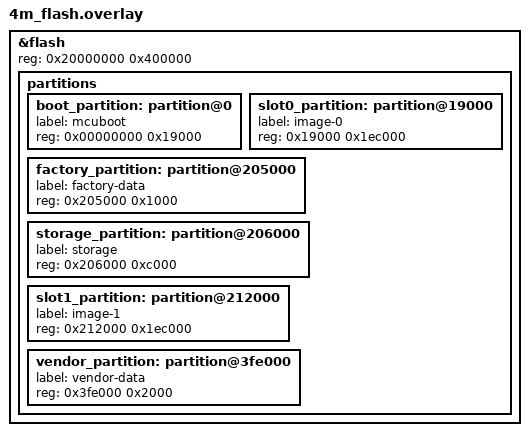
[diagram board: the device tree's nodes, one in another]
/*
 * In case of change partitions size - check if factory data size is correct
 * in matter/connectedhomeip/config/telink/chip-module/CMakeLists.txt, variable "FD_SEEK"
 * Also check matter/connectedhomeip/config/telink/chip-module/generate_factory_data.cmake,
 * variable "FD_OFFSET" and argument "size"
 */

&flash {
	reg = <0x20000000 0x400000>;

	partitions {
		/delete-node/ partition@0;
		/delete-node/ partition@20000;
		/delete-node/ partition@88000;
		/delete-node/ partition@f0000;
		/delete-node/ partition@f4000;
		/delete-node/ partition@fe000;
		boot_partition: partition@0 {
			label = "mcuboot";
			reg = <0x00000000 0x19000>;
		};
		slot0_partition: partition@19000 {
			label = "image-0";
			reg = <0x19000 0x1ec000>;
		};
		factory_partition: partition@205000 {
			label = "factory-data";
			reg = <0x205000 0x1000>;
		};
		storage_partition: partition@206000 {
			label = "storage";
			reg = <0x206000 0xc000>;
		};
		slot1_partition: partition@212000 {
			label = "image-1";
			reg = <0x212000 0x1ec000>;
		};
		vendor_partition: partition@3fe000 {
			label = "vendor-data";
			reg = <0x3fe000 0x2000>;
		};
	};
};
